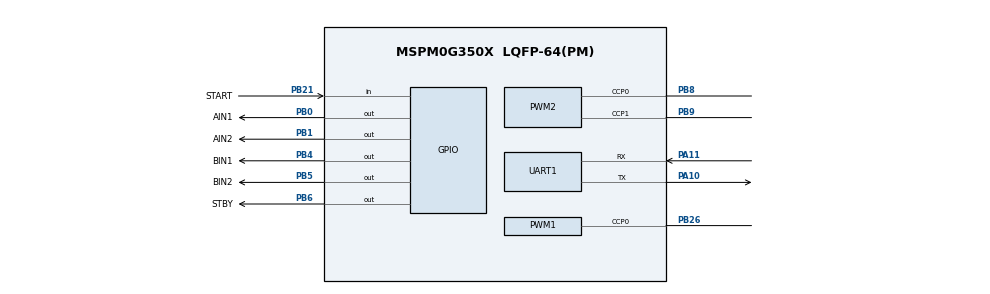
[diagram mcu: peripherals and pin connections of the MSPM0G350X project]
/**
 *
 * @cliArgs --device "MSPM0G350X" --part "Default" --package "LQFP-64(PM)" --product "mspm0_sdk@2.10.00.04"
 * @versions {"tool":"1.28.0+4696"}
 */

/**
 * Import the modules used in this configuration.
 */
const GPIO   = scripting.addModule("/ti/driverlib/GPIO", {}, false);
const GPIO1  = GPIO.addInstance();
const GPIO2  = GPIO.addInstance();
const GPIO3  = GPIO.addInstance();
const PWM    = scripting.addModule("/ti/driverlib/PWM", {}, false);
const PWM1   = PWM.addInstance();
const PWM2   = PWM.addInstance();
const SYSCTL = scripting.addModule("/ti/driverlib/SYSCTL");
const TIMER  = scripting.addModule("/ti/driverlib/TIMER", {}, false);
const TIMER1 = TIMER.addInstance();
const UART   = scripting.addModule("/ti/driverlib/UART", {}, false);
const UART1  = UART.addInstance();

/**
 * Write custom configuration values to the imported modules.
 */
GPIO1.$name                               = "GPIO_LED";
GPIO1.associatedPins[0].$name             = "STATUS";
GPIO1.associatedPins[0].launchPadShortcut = "LED2GreenEn";

const Board = scripting.addModule("/ti/driverlib/Board", {}, false);

GPIO2.$name                              = "GPIO_KEY";
GPIO2.associatedPins[0].$name            = "START";
GPIO2.associatedPins[0].direction        = "INPUT";
GPIO2.associatedPins[0].internalResistor = "PULL_UP";
GPIO2.associatedPins[0].pin.$assign      = "PB21";

GPIO3.$name                         = "GPIO_Motor";
GPIO3.port                          = "PORTB";
GPIO3.associatedPins.create(5);
GPIO3.associatedPins[0].$name       = "AIN1";
GPIO3.associatedPins[0].pin.$assign = "PB0";
GPIO3.associatedPins[1].$name       = "AIN2";
GPIO3.associatedPins[1].pin.$assign = "PB1";
GPIO3.associatedPins[2].$name       = "BIN1";
GPIO3.associatedPins[2].pin.$assign = "PB4";
GPIO3.associatedPins[3].$name       = "BIN2";
GPIO3.associatedPins[3].pin.$assign = "PB5";
GPIO3.associatedPins[4].$name       = "STBY";
GPIO3.associatedPins[4].pin.$assign = "PB6";

PWM1.$name                              = "PWM_Buzzer";
PWM1.ccIndex                            = [0];
PWM1.clockDivider                       = 8;
PWM1.clockPrescale                      = 32;
PWM1.timerCount                         = 100;
PWM1.PWM_CHANNEL_0.$name                = "ti_driverlib_pwm_PWMTimerCC0";
PWM1.PWM_CHANNEL_0.dutyCycle            = 50;
PWM1.ccp0PinConfig.$name                = "ti_driverlib_gpio_GPIOPinGeneric2";
PWM1.ccp0PinConfig.direction            = scripting.forceWrite("OUTPUT");
PWM1.ccp0PinConfig.hideOutputInversion  = scripting.forceWrite(false);
PWM1.ccp0PinConfig.onlyInternalResistor = scripting.forceWrite(false);
PWM1.ccp0PinConfig.passedPeripheralType = scripting.forceWrite("Digital");
PWM1.peripheral.$assign                 = "TIMG6";
PWM1.peripheral.ccp0Pin.$assign         = "PB26";

PWM2.$name                              = "PWM_Motors";
PWM2.clockDivider                       = 4;
PWM2.peripheral.$assign                 = "TIMA0";
PWM2.peripheral.ccp0Pin.$assign         = "PB8";
PWM2.peripheral.ccp1Pin.$assign         = "PB9";
PWM2.PWM_CHANNEL_0.$name                = "ti_driverlib_pwm_PWMTimerCC1";
PWM2.PWM_CHANNEL_1.$name                = "ti_driverlib_pwm_PWMTimerCC2";
PWM2.ccp0PinConfig.$name                = "ti_driverlib_gpio_GPIOPinGeneric3";
PWM2.ccp0PinConfig.direction            = scripting.forceWrite("OUTPUT");
PWM2.ccp0PinConfig.hideOutputInversion  = scripting.forceWrite(false);
PWM2.ccp0PinConfig.onlyInternalResistor = scripting.forceWrite(false);
PWM2.ccp0PinConfig.passedPeripheralType = scripting.forceWrite("Digital");
PWM2.ccp1PinConfig.$name                = "ti_driverlib_gpio_GPIOPinGeneric4";
PWM2.ccp1PinConfig.direction            = scripting.forceWrite("OUTPUT");
PWM2.ccp1PinConfig.hideOutputInversion  = scripting.forceWrite(false);
PWM2.ccp1PinConfig.onlyInternalResistor = scripting.forceWrite(false);
PWM2.ccp1PinConfig.passedPeripheralType = scripting.forceWrite("Digital");

SYSCTL.forceDefaultClkConfig = true;
SYSCTL.SYSPLL_CLK2XEn        = true;
SYSCTL.SYSPLL_CLK2XDiv       = 3;
SYSCTL.MCLKSource            = "HSCLK";
SYSCTL.HSCLKSource           = "SYSPLLCLK2X";

TIMER1.$name              = "TIM_CTRL";
TIMER1.timerMode          = "PERIODIC";
TIMER1.timerPeriod        = "5 ms";
TIMER1.interrupts         = ["ZERO"];
TIMER1.timerClkDiv        = 8;
TIMER1.timerClkPrescale   = 32;
TIMER1.peripheral.$assign = "TIMG7";

UART1.$name                            = "UART0_Debug";
UART1.targetBaudRate                   = 115200;
UART1.peripheral.rxPin.$assign         = "PA11";
UART1.peripheral.txPin.$assign         = "PA10";
UART1.txPinConfig.$name                = "ti_driverlib_gpio_GPIOPinGeneric0";
UART1.txPinConfig.direction            = scripting.forceWrite("OUTPUT");
UART1.txPinConfig.hideOutputInversion  = scripting.forceWrite(false);
UART1.txPinConfig.onlyInternalResistor = scripting.forceWrite(false);
UART1.txPinConfig.passedPeripheralType = scripting.forceWrite("Digital");
UART1.rxPinConfig.$name                = "ti_driverlib_gpio_GPIOPinGeneric1";
UART1.rxPinConfig.hideOutputInversion  = scripting.forceWrite(false);
UART1.rxPinConfig.onlyInternalResistor = scripting.forceWrite(false);
UART1.rxPinConfig.passedPeripheralType = scripting.forceWrite("Digital");

/**
 * Pinmux solution for unlocked pins/peripherals. This ensures that minor changes to the automatic solver in a future
 * version of the tool will not impact the pinmux you originally saw.  These lines can be completely deleted in order to
 * re-solve from scratch.
 */
GPIO1.associatedPins[0].pin.$suggestSolution = "PB27";
Board.peripheral.$suggestSolution            = "DEBUGSS";
Board.peripheral.swclkPin.$suggestSolution   = "PA20";
Board.peripheral.swdioPin.$suggestSolution   = "PA19";
SYSCTL.peripheral.$suggestSolution           = "SYSCTL";
UART1.peripheral.$suggestSolution            = "UART0";
